AUTOSAR XML (schema 4-2-2)
package /ComponentTypes
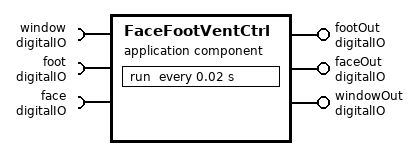
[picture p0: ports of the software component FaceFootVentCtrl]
  application sw component type FaceFootVentCtrl
    require port window: nonqueued-receiver-com-spec{data-element=boolean, init-value=0}, required-interface=digitalIO
    require port foot: nonqueued-receiver-com-spec{data-element=boolean, init-value=0}, required-interface=digitalIO
    require port face: nonqueued-receiver-com-spec{data-element=boolean, init-value=0}, required-interface=digitalIO
    provide port footOut: nonqueued-sender-com-spec=boolean, provided-interface=digitalIO
    provide port faceOut: nonqueued-sender-com-spec=boolean, provided-interface=digitalIO
    provide port windowOut: nonqueued-sender-com-spec=boolean, provided-interface=digitalIO
    behavior FaceFootVentCtrl_InternalBehavior
      data received event DRT_run_face_boolean: start-on-event=run, data=face.boolean
      data received event DRT_run_foot_boolean: start-on-event=run, data=foot.boolean
      data received event DRT_run_window_boolean: start-on-event=run, data=window.boolean
      timing event TMT_run: start-on-event=run, period=0.02
      runnable run
        data-receive-point-by-arguments:
          access REC_face_boolean: accessed-variable=face.boolean
          access REC_foot_boolean: accessed-variable=foot.boolean
          access REC_window_boolean: accessed-variable=window.boolean
        data-send-points:
          access SEND_faceOut_boolean: accessed-variable=faceOut.boolean
          access SEND_footOut_boolean: accessed-variable=footOut.boolean
          access SEND_windowOut_boolean: accessed-variable=windowOut.boolean
  swc implementation FaceFootVentCtrl_Implementation: behavior=FaceFootVentCtrl_InternalBehavior
